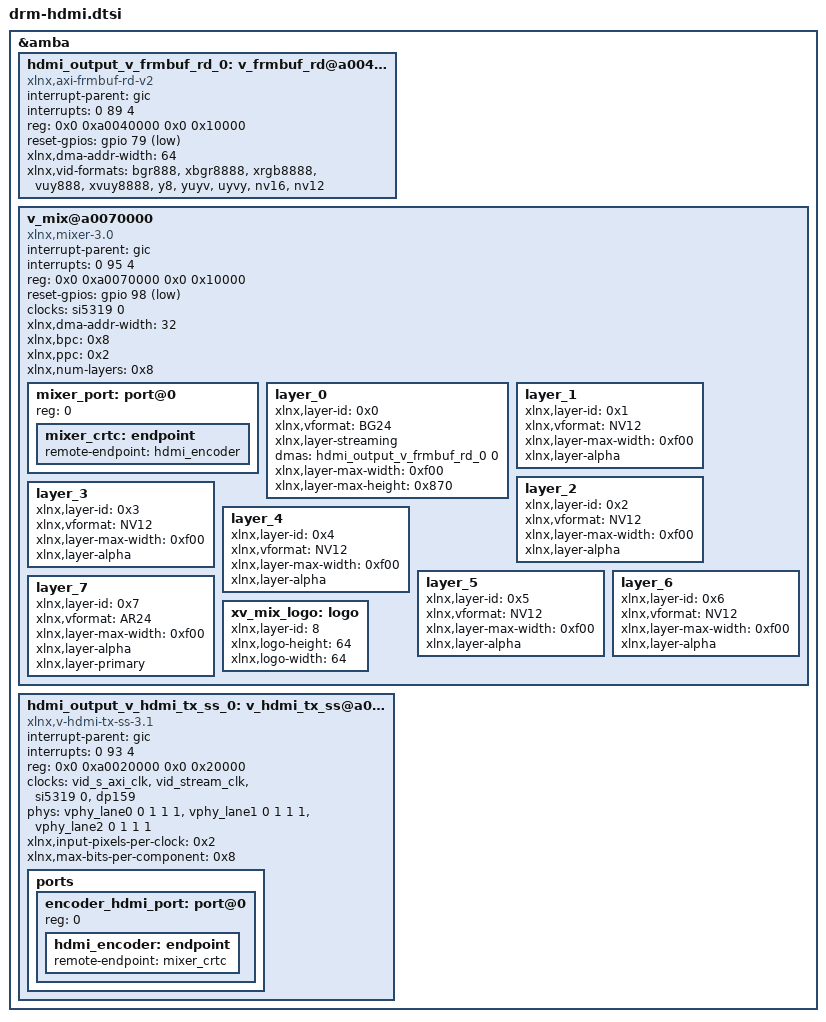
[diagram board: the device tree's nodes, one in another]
&amba {
	hdmi_output_v_frmbuf_rd_0: v_frmbuf_rd@a0040000 {
		compatible = "xlnx,axi-frmbuf-rd-v2";
		#dma-cells = <1>;
		interrupt-parent = <&gic>;
		interrupts = <0 89 4>;
		reg = <0x0 0xa0040000 0x0 0x10000>;
		reset-gpios = <&gpio 79 1>;
		xlnx,dma-addr-width = <64>;
		xlnx,vid-formats = "bgr888","xbgr8888","xrgb8888","vuy888","xvuy8888","y8","yuyv","uyvy","nv16","nv12";
	};

	v_mix@a0070000 {
		compatible = "xlnx,mixer-3.0";
		interrupt-parent = <&gic>;
		interrupts = <0 95 4>;
		reg = <0x0 0xa0070000 0x0 0x10000>;
		reset-gpios = <&gpio 98 1>;
		clocks = <&si5319 0>;
		xlnx,dma-addr-width=<32>;
		xlnx,bpc = <0x8>;
		xlnx,ppc = <0x2>;
		xlnx,num-layers = <0x8>;

		mixer_port: port@0 {
            reg = <0>;
            mixer_crtc: endpoint {
                remote-endpoint = <&hdmi_encoder>;
            };
        };

		layer_0 {
			xlnx,layer-id = <0x0>;
			xlnx,vformat = "BG24";
			xlnx,layer-streaming;
			dmas = <&hdmi_output_v_frmbuf_rd_0 0>;
			dma-names = "dma0";
			xlnx,layer-max-width = <0xf00>;
			xlnx,layer-max-height = <0x870>;
		};

	    layer_1 {
           	xlnx,layer-id = <0x1>;
	        xlnx,vformat = "NV12";
			xlnx,layer-max-width = <0xf00>;
			xlnx,layer-alpha;
           };

		layer_2 {
			xlnx,layer-id = <0x2>;
			xlnx,vformat = "NV12";
			xlnx,layer-max-width = <0xf00>;
			xlnx,layer-alpha;
		};

		layer_3 {
			xlnx,layer-id = <0x3>;
			xlnx,vformat = "NV12";
			xlnx,layer-max-width = <0xf00>;
			xlnx,layer-alpha;
		};

	    layer_4 {
           	xlnx,layer-id = <0x4>;
	        xlnx,vformat = "NV12";
			xlnx,layer-max-width = <0xf00>;
			xlnx,layer-alpha;
		};

		layer_5 {
			xlnx,layer-id = <0x5>;
			xlnx,vformat = "NV12";
			xlnx,layer-max-width = <0xf00>;
			xlnx,layer-alpha;
		};

		layer_6 {
			xlnx,layer-id = <0x6>;
			xlnx,vformat = "NV12";
			xlnx,layer-max-width = <0xf00>;
			xlnx,layer-alpha;
		};
		
		layer_7 {
			xlnx,layer-id = <0x7>;
			xlnx,vformat = "AR24";

			xlnx,layer-max-width = <0xf00>;
			xlnx,layer-alpha;
			xlnx,layer-primary;
		};
		
		xv_mix_logo: logo {
				xlnx,layer-id = <8>;
				xlnx,logo-height = <64>;
				xlnx,logo-width = <64>;
				/* xlnx,logo-pixel-alpha; */
			};

	};

	hdmi_output_v_hdmi_tx_ss_0: v_hdmi_tx_ss@a0020000 {
		compatible = "xlnx,v-hdmi-tx-ss-3.1";
		interrupt-parent = <&gic>;
		interrupts = <0 93 4>;
		interrupt-names = "hdmitx";
		reg = <0x0 0xa0020000 0x0 0x20000>;
		reg-names = "hdmi-txss";
		clocks = <&vid_s_axi_clk>, <&vid_stream_clk>, <&si5319 0>, <&dp159>;
		clock-names = "axi-lite", "video", "txref-clk", "retimer-clk";
		phy-names = "hdmi-phy0", "hdmi-phy1", "hdmi-phy2";
		phys = <&vphy_lane0 0 1 1 1>, <&vphy_lane1 0 1 1 1>, <&vphy_lane2 0 1 1 1>;

		xlnx,input-pixels-per-clock = <0x2>;
		xlnx,max-bits-per-component = <0x8>;
	
		ports {
			#address-cells = <1>;
			#size-cells = <0>;		
			encoder_hdmi_port: port@0 {
				reg = <0>;
				hdmi_encoder: endpoint {
					remote-endpoint = <&mixer_crtc>;
				};
			};
		};	
	};
};
